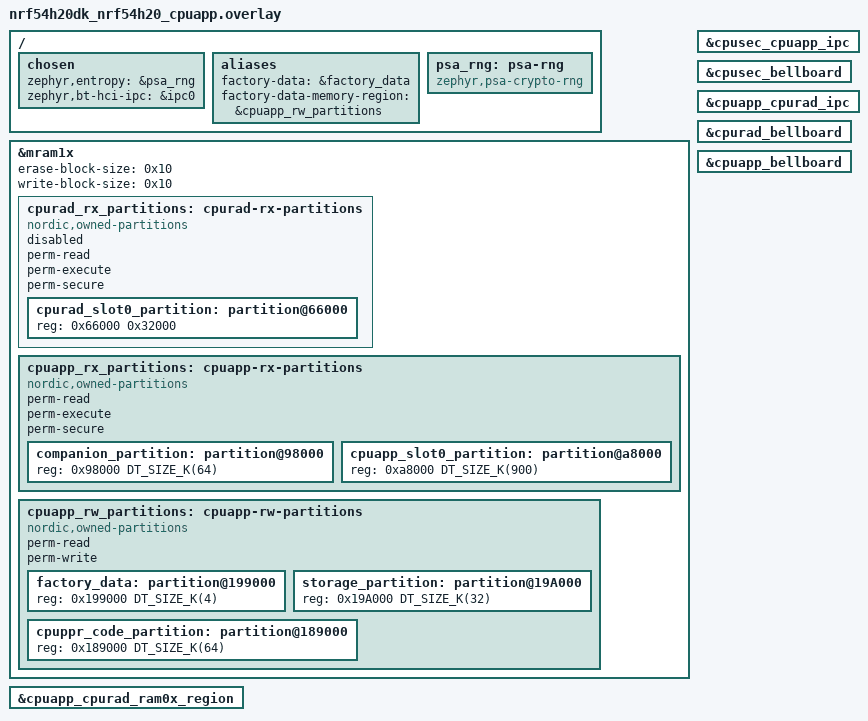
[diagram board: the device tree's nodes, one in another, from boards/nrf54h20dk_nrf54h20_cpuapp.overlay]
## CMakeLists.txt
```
#
# Copyright (c) 2021 Nordic Semiconductor ASA
#
# SPDX-License-Identifier: LicenseRef-Nordic-5-Clause
#

cmake_minimum_required(VERSION 3.20.0)

find_package(Zephyr REQUIRED HINTS $ENV{ZEPHYR_BASE})
project(matter-lock)

# Enable GNU STD support.
include(${ZEPHYR_CONNECTEDHOMEIP_MODULE_DIR}/config/nrfconnect/app/enable-gnu-std.cmake)

# NORDIC SDK APP START

# Include Data Model utils
include(${ZEPHYR_NRF_MODULE_DIR}/samples/matter/common/cmake/data_model.cmake)

target_include_directories(app PRIVATE
    src
    ${CONFIG_NCS_MATTER_ZAP_FILES_PATH}
)

SET(access_srcs src/access/access_data_types.cpp
              src/access/access_manager_credentials.cpp
              src/access/access_manager_users.cpp
              src/access/access_manager.cpp
              src/access/access_storage.cpp
              )

if(CONFIG_LOCK_SCHEDULES)
    LIST(APPEND access_srcs src/access/access_manager_schedules.cpp)
endif()

target_sources(app PRIVATE
    src/app_task.cpp
    src/bolt_lock_manager.cpp
    src/main.cpp
    src/zcl_callbacks.cpp
    ${access_srcs}
)

if(CONFIG_THREAD_WIFI_SWITCHING)
    target_sources(app PRIVATE
        src/thread_wifi_switch.cpp
    )
endif()

# Do not treat warnings as errors while the variable may be uninitialized for this sample data model.
# In the door-lock-server implementation, there is a warning that the C++ "optional"
# variable may be uninitialized, but actually, it is wrongly interpreted by the Zephyr toolchain.
target_compile_options(matter-data-model PRIVATE -Wno-error=maybe-uninitialized)

ncs_configure_data_model(
    ZAP_FILE ${CMAKE_CURRENT_SOURCE_DIR}/${CONFIG_NCS_MATTER_ZAP_FILES_PATH}/lock.zap
)

# NORDIC SDK APP END
```

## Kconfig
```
#
# Copyright (c) 2021 Nordic Semiconductor
#
# SPDX-License-Identifier: LicenseRef-Nordic-5-Clause
#

mainmenu "Matter Lock sample application"

config LOCK_MAX_NUM_USERS
	int "Maximum number of users supported by the lock"
	default 10

config LOCK_MAX_NUM_CREDENTIALS_PER_USER
	int "Maximum total number of credentials per one user supported by the lock"
	default 4

config LOCK_MAX_NUM_CREDENTIALS_PER_TYPE
	int "Maximum number of credentials of given type supported by the lock"
	default 15

config LOCK_MAX_CREDENTIAL_LENGTH
	int "Maximum length of the single credential supported by the lock"
	default 10

config LOCK_PASS_CREDENTIALS_TO_SET_LOCK_STATE
	bool "Pass used credentials when setting the lock state"
	help
	  This option should stay disabled until TC-DRLK-2.3 is fixed.
	  Related issue: https://github.com/project-chip/connectedhomeip/issues/38222

config LOCK_SCHEDULES
	bool "Support for WeekDay, YearDay and Holiday schedules in lock"
	help
	  This option adds support for an optional Timed Schedule Access Lock feature.
	  You can use Week Day, Year Day and Holiday schedules to restrict access for a
	  specific user for a defined time window. For example, use it to
	  give the user access only for three days in week.

if LOCK_SCHEDULES

config LOCK_MAX_WEEKDAY_SCHEDULES_PER_USER
	int "Maximum number of WeekDay schedules per one user supported by the lock"
	default 5

config LOCK_MAX_YEARDAY_SCHEDULES_PER_USER
	int "Maximum number of YearDay schedules per one user supported by the lock"
	default 5

config LOCK_MAX_HOLIDAY_SCHEDULES
	int "Maximum number of Holiday schedules supported by the lock"
	default 5

endif

config LOCK_ENABLE_DEBUG
	bool "Enable debug features to print users and credentials"
	depends on SHELL
	help
	  Debug features allows to checking and printing current users, their state, and
	  associated credentials. Use these with shell commands combinations to read saved credentials
	  or users, and manage them (add, clear, read).

if LOCK_ENABLE_DEBUG

config LOCK_PRINT_STORAGE_STATUS
	bool "Print storage status after each store call"
	help
	  Debug feature to print the debug-level log that contains information of the entry being stored
	  to persistent storage and how many bytes are left to store the new entry. It can be used to verify
	  whether credential, schedule or user entries are written properly to persistent storage.
	  This option should be disabled in production firmware
	  version.

# This should be deterined based on the maximum possible command length that depends on the LOCK_MAX_CREDENTIAL_LENGTH
config SHELL_CMD_BUFF_SIZE
	default 300

endif

config STATE_LEDS
	bool "Use LEDs to indicate the device state"
	default y
	help
	  Use LEDs to render the current state of the device such as the progress of commissioning of
	  the device into a network or the factory reset initiation. Note that setting this option to
	  'n' does not disable the LED indicating the state of the simulated bolt.

config THREAD_WIFI_SWITCHING
	bool "Switching between Thread and Wi-Fi"
	depends on SOC_SERIES_NRF53X
	depends on NET_L2_OPENTHREAD
	depends on CHIP_WIFI
	depends on !CHIP_FACTORY_RESET_ERASE_SETTINGS
	select EXPERIMENTAL
	help
	  Build the application with both Thread and Wi-Fi support and initialize
	  either transport based on the current configuration. A user can switch
	  between Thread and Wi-Fi by pressing and holding Button 3 for more than
	  10 seconds. During the switching, the device is automatically factory
	  reset and rebooted.

if THREAD_WIFI_SWITCHING

config THREAD_WIFI_SWITCHING_SHELL
	bool "Shell command for switching between Thread and Wi-Fi"
	default y if SHELL
	help
	  Add "switch_transport" shell command that initiates switching between
	  Thread and Wi-Fi transport for Matter protocol stack.

endif # THREAD_WIFI_SWITCHING

# Sample configuration used for Thread networking
if OPENTHREAD

choice OPENTHREAD_NORDIC_LIBRARY_CONFIGURATION
	default OPENTHREAD_NORDIC_LIBRARY_MTD
endchoice

choice OPENTHREAD_DEVICE_TYPE
	default OPENTHREAD_MTD
endchoice

config CHIP_ENABLE_ICD_SUPPORT
	default y

# Reduce Thread TX output power to 0 dBm for SED device
config OPENTHREAD_DEFAULT_TX_POWER
	int
	default 0

endif # OPENTHREAD

if CHIP_WIFI

config NRF_WIFI_LOW_POWER
	default y

endif # CHIP_WIFI

config NCS_MATTER_PERSISTENT_STORAGE
	default y

# PSA SSF Crypto Client is not ready for the secure storage backend
if !PSA_SSF_CRYPTO_CLIENT

config NCS_MATTER_SECURE_STORAGE_BACKEND
	default y if !CHIP_WIFI

config NCS_MATTER_SETTINGS_STORAGE_BACKEND
	default n if !CHIP_WIFI

endif

# Increase the storage capacity if the schedules are enabled with secure storage
# This also implies increasing of the OT and Matter stacks because some operations
# performed during commissioning seem to allocate stack buffers based on the
# maximum possible secure asset size.
if LOCK_SCHEDULES && NCS_MATTER_SECURE_STORAGE_BACKEND

config NCS_MATTER_SECURE_STORAGE_MAX_ENTRY_NUMBER
	default 128

config TRUSTED_STORAGE_BACKEND_AEAD_MAX_DATA_SIZE
	default 3072

config OPENTHREAD_THREAD_STACK_SIZE
	default 7168

config CHIP_TASK_STACK_SIZE
	default 10240

config MAIN_STACK_SIZE
	default 7168

endif

source "${ZEPHYR_CONNECTEDHOMEIP_MODULE_DIR}/config/nrfconnect/chip-module/Kconfig.features"
source "${ZEPHYR_CONNECTEDHOMEIP_MODULE_DIR}/config/nrfconnect/chip-module/Kconfig.defaults"
source "${ZEPHYR_NRF_MODULE_DIR}/samples/matter/common/src/Kconfig"
source "Kconfig.zephyr"
```

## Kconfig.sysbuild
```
#
# Copyright (c) 2023 Nordic Semiconductor ASA
#
# SPDX-License-Identifier: LicenseRef-Nordic-5-Clause
#

config PARTITION_MANAGER
	default n if (SOC_SERIES_NRF52X || SOC_NRF54L15 || SOC_NRF54LM20A) && \
		!TRUSTED_EXECUTION_NONSECURE

# This config has to be enabled manually for variants with shields, because sysbuild does not support it.
config WIFI_NRF70
	default y if BOARD_NRF7002DK

#### Radio core selection
config NRF_DEFAULT_IPC_RADIO
	default y

# Enable IEEE802.15.4 serialization to network core
# This config automatically pulls in the `overlay-802154.conf` in the ipc_radio image
config NETCORE_IPC_RADIO_IEEE802154
	default y if SOC_SERIES_NRF53X && !WIFI_NRF70

# Enable Bluetooth serialization to network core
# This config automatically pulls in the `overlay-bt_hci_ipc.conf` in the ipc_radio image
config NETCORE_IPC_RADIO_BT_HCI_IPC
	default y if SOC_SERIES_NRF53X

#### Bootloader
choice BOOTLOADER
	default BOOTLOADER_MCUBOOT if !BOARD_NRF21540DK
endchoice

if BOOTLOADER_MCUBOOT

#### DFU multi-image support
config DFU_MULTI_IMAGE_PACKAGE_BUILD
	default y

config DFU_MULTI_IMAGE_PACKAGE_APP
	default y

config PM_EXTERNAL_FLASH_MCUBOOT_SECONDARY
	default y

#### DFU network core configuration
if SOC_SERIES_NRF53X

choice MCUBOOT_MODE
	default MCUBOOT_MODE_OVERWRITE_ONLY
endchoice

choice BOOT_SIGNATURE_TYPE
	default BOOT_SIGNATURE_TYPE_RSA
endchoice

config SECURE_BOOT_NETCORE
	default y

config NETCORE_APP_UPDATE
	default y

config DFU_MULTI_IMAGE_PACKAGE_NET
	default y

endif # SOC_SERIES_NRF53X

if BOARD_NRF54L15DK || BOARD_NRF54LM20DK

# Disable checking the external drivers for nRF54L15 and nRF54LM20 DKs.
config PM_OVERRIDE_EXTERNAL_DRIVER_CHECK
	default y

endif # BOARD_NRF54L15DK || BOARD_NRF54LM20DK

endif # BOOTLOADER_MCUBOOT

# Store the Wi-Fi firmware patch on external flash by default for nRF5340 with nRF7002
if WIFI_NRF70 && SOC_NRF5340_CPUAPP

choice WIFI_PATCHES_EXT_FLASH_SUPPORT
	default WIFI_PATCHES_EXT_FLASH_STORE

endchoice

config DFU_MULTI_IMAGE_PACKAGE_WIFI_FW_PATCH
	default y

endif # WIFI_NRF70

#### Enable generating factory data
config MATTER_FACTORY_DATA_GENERATE
	default y if !BOARD_NRF21540DK

source "share/sysbuild/Kconfig"
```

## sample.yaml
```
sample:
  description: Matter Lock example
  name: Matter Lock
tests:
  sample.matter.lock.debug:
    sysbuild: true
    build_only: true
    integration_platforms:
      - nrf52840dk/nrf52840
      - nrf5340dk/nrf5340/cpuapp
      - nrf7002dk/nrf5340/cpuapp
      - nrf7002dk/nrf5340/cpuapp/nrf7001
      - nrf54l15pdk/nrf54l15/cpuapp
      - nrf54h20dk/nrf54h20/cpuapp
    platform_allow: nrf52840dk/nrf52840 nrf5340dk/nrf5340/cpuapp nrf7002dk/nrf5340/cpuapp
      nrf7002dk/nrf5340/cpuapp/nrf7001 nrf54l15pdk/nrf54l15/cpuapp
      nrf54h20dk/nrf54h20/cpuapp
    tags: sysbuild
  sample.matter.lock.release:
    sysbuild: true
    build_only: true
    extra_args: FILE_SUFFIX=release
    integration_platforms:
      - nrf52840dk/nrf52840
      - nrf5340dk/nrf5340/cpuapp
      - nrf7002dk/nrf5340/cpuapp
      - nrf7002dk/nrf5340/cpuapp/nrf7001
      - nrf54l15pdk/nrf54l15/cpuapp
    platform_allow: nrf52840dk/nrf52840 nrf5340dk/nrf5340/cpuapp nrf7002dk/nrf5340/cpuapp
      nrf7002dk/nrf5340/cpuapp/nrf7001 nrf54l15pdk/nrf54l15/cpuapp
    tags: sysbuild
  sample.matter.lock.lto:
    sysbuild: true
    build_only: true
    extra_args: CONFIG_LTO=y CONFIG_ISR_TABLES_LOCAL_DECLARATION=y
    integration_platforms:
      - nrf52840dk/nrf52840
      - nrf5340dk/nrf5340/cpuapp
      - nrf7002dk/nrf5340/cpuapp
      - nrf7002dk/nrf5340/cpuapp/nrf7001
      - nrf54l15pdk/nrf54l15/cpuapp
    platform_allow: nrf52840dk/nrf52840 nrf5340dk/nrf5340/cpuapp nrf7002dk/nrf5340/cpuapp
      nrf7002dk/nrf5340/cpuapp/nrf7001 nrf54l15pdk/nrf54l15/cpuapp
    tags: sysbuild
  sample.matter.lock.smp_dfu:
    sysbuild: true
    build_only: true
    extra_args: CONFIG_CHIP_DFU_OVER_BT_SMP=y
    integration_platforms:
      - nrf52840dk/nrf52840
      - nrf5340dk/nrf5340/cpuapp
      - nrf7002dk/nrf5340/cpuapp
      - nrf7002dk/nrf5340/cpuapp/nrf7001
      - nrf54l15pdk/nrf54l15/cpuapp
    platform_allow: nrf52840dk/nrf52840 nrf5340dk/nrf5340/cpuapp nrf7002dk/nrf5340/cpuapp
      nrf7002dk/nrf5340/cpuapp/nrf7001 nrf54l15pdk/nrf54l15/cpuapp
    tags: sysbuild
  sample.matter.lock.no_dfu.no_fd:
    sysbuild: true
    build_only: true
    integration_platforms:
      - nrf21540dk/nrf52840
    platform_allow: >
      nrf21540dk/nrf52840
    tags: sysbuild
  sample.matter.lock.thread_wifi_switched.lto.smp_dfu:
    sysbuild: true
    build_only: true
    extra_args: lock_SHIELD=nrf7002ek multiprotocol_rpmsg_SHIELD=nrf7002ek_coex
      FILE_SUFFIX=thread_wifi_switched SB_CONFIG_WIFI_PATCHES_EXT_FLASH_STORE=y
      SB_CONFIG_MCUBOOT_UPDATEABLE_IMAGES=3 CONFIG_CHIP_DFU_OVER_BT_SMP=y
      SB_CONFIG_WIFI_NRF700X=y SB_CONFIG_DFU_MULTI_IMAGE_PACKAGE_WIFI_FW_PATCH=y
    integration_platforms:
      - nrf5340dk/nrf5340/cpuapp
    platform_allow: nrf5340dk/nrf5340/cpuapp
    tags: sysbuild
  sample.matter.lock.nus:
    sysbuild: true
    build_only: true
    extra_args: CONFIG_CHIP_NUS=y CONFIG_BT_FIXED_PASSKEY=y CONFIG_CHIP_NUS_FIXED_PASSKEY=112233
    integration_platforms:
      - nrf52840dk/nrf52840
      - nrf5340dk/nrf5340/cpuapp
    platform_allow: nrf52840dk/nrf52840 nrf5340dk/nrf5340/cpuapp
    tags: sysbuild
  samples.matter.lock.certification:
    sysbuild: true
    build_only: true
    extra_args: lock_SNIPPET=diagnostic-logs
    integration_platforms:
      - nrf52840dk/nrf52840
      - nrf5340dk/nrf5340/cpuapp
      - nrf54l15pdk/nrf54l15/cpuapp
    platform_allow: nrf52840dk/nrf52840 nrf5340dk/nrf5340/cpuapp nrf54l15pdk/nrf54l15/cpuapp
    tags: sysbuild
```

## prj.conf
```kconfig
#
# Copyright (c) 2022 Nordic Semiconductor ASA
#
# SPDX-License-Identifier: LicenseRef-Nordic-5-Clause
#

# This sample uses Kconfig.defaults to set options common for all
# samples. This file should contain only options specific for this sample
# or overrides of default values.

# Enable CHIP
CONFIG_CHIP=y
CONFIG_CHIP_PROJECT_CONFIG="src/chip_project_config.h"
# 32774 == 0x8006 (example lock-app)
CONFIG_CHIP_DEVICE_PRODUCT_ID=32774
CONFIG_STD_CPP17=y

# Enable Matter extended announcement and increase duration to 1 hour.
CONFIG_CHIP_BLE_EXT_ADVERTISING=y
CONFIG_CHIP_BLE_ADVERTISING_DURATION=60

# Add support for LEDs and buttons on Nordic development kits
CONFIG_DK_LIBRARY=y

# Bluetooth Low Energy configuration
CONFIG_BT_DEVICE_NAME="MatterLock"

# Suspend devices when the CPU goes into sleep
CONFIG_PM_DEVICE=y

# Other settings
CONFIG_THREAD_NAME=y
CONFIG_MPU_STACK_GUARD=y
CONFIG_RESET_ON_FATAL_ERROR=n
CONFIG_CHIP_LIB_SHELL=y
CONFIG_NCS_MATTER_TEST_SHELL=y

# Reduce application size
CONFIG_USE_SEGGER_RTT=n
CONFIG_MATTER_LOG_LEVEL_INF=y
CONFIG_CHIP_APP_LOG_LEVEL=3

# Enable Factory Data feature
CONFIG_CHIP_FACTORY_DATA=y
CONFIG_CHIP_FACTORY_DATA_BUILD=y
```

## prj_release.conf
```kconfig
#
# Copyright (c) 2022 Nordic Semiconductor ASA
#
# SPDX-License-Identifier: LicenseRef-Nordic-5-Clause
#

# This sample uses Kconfig.defaults to set options common for all
# samples. This file should contain only options specific for this sample
# or overrides of default values.

# Enable CHIP
CONFIG_CHIP=y
CONFIG_CHIP_PROJECT_CONFIG="src/chip_project_config.h"
# 32774 == 0x8006 (example lock-app)
CONFIG_CHIP_DEVICE_PRODUCT_ID=32774
CONFIG_STD_CPP17=y

# Enable Matter extended announcement and increase duration to 1 hour.
CONFIG_CHIP_BLE_EXT_ADVERTISING=y
CONFIG_CHIP_BLE_ADVERTISING_DURATION=60

# Add support for LEDs and buttons on Nordic development kits
CONFIG_DK_LIBRARY=y

# Bluetooth Low Energy configuration
CONFIG_BT_DEVICE_NAME="MatterLock"

# Suspend devices when the CPU goes into sleep
CONFIG_PM_DEVICE=y

# Enable system reset on fatal error
CONFIG_RESET_ON_FATAL_ERROR=y

# Try to disable unused RAM blocks to reduce power consumption
CONFIG_RAM_POWER_DOWN_LIBRARY=y

# Disable all debug features
CONFIG_USE_SEGGER_RTT=n
CONFIG_SHELL=n
CONFIG_OPENTHREAD_SHELL=n
CONFIG_CONSOLE=n
CONFIG_UART_CONSOLE=n
CONFIG_SERIAL=n
CONFIG_LOG=n
CONFIG_LOG_MODE_MINIMAL=n
CONFIG_ASSERT_VERBOSE=n
CONFIG_ASSERT_NO_FILE_INFO=y
CONFIG_PRINTK=n
CONFIG_PRINTK_SYNC=n
CONFIG_THREAD_NAME=n
CONFIG_BOOT_BANNER=n

# Enable Factory Data feature
CONFIG_CHIP_FACTORY_DATA=y
CONFIG_CHIP_FACTORY_DATA_BUILD=y

# Enable Watchdog
CONFIG_NCS_MATTER_WATCHDOG=y

# Enable LTO to decrease the flash usage.
CONFIG_LTO=y
CONFIG_ISR_TABLES_LOCAL_DECLARATION=y
```

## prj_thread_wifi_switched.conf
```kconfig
#
# Copyright (c) 2022 Nordic Semiconductor ASA
#
# SPDX-License-Identifier: LicenseRef-Nordic-5-Clause
#

# This sample uses Kconfig.defaults to set options common for all
# samples. This file should contain only options specific for this sample
# or overrides of default values.

# Enable CHIP
CONFIG_CHIP=y
CONFIG_CHIP_PROJECT_CONFIG="src/chip_project_config.h"
# 32774 == 0x8006 (example lock-app)
CONFIG_CHIP_DEVICE_PRODUCT_ID=32774
CONFIG_STD_CPP17=y

# Enable Matter extended announcement and increase duration to 1 hour.
CONFIG_CHIP_BLE_EXT_ADVERTISING=y
CONFIG_CHIP_BLE_ADVERTISING_DURATION=60

# Add support for LEDs and buttons on Nordic development kits
CONFIG_DK_LIBRARY=y

# Bluetooth Low Energy configuration
CONFIG_BT_DEVICE_NAME="MatterLock"

# Other settings
CONFIG_MPU_STACK_GUARD=y
CONFIG_RESET_ON_FATAL_ERROR=n

# Enable switching between Thread and Wi-Fi variants
CONFIG_THREAD_WIFI_SWITCHING=y
CONFIG_THREAD_WIFI_SWITCHING_SHELL=y
CONFIG_CHIP_WIFI=y
CONFIG_NET_L2_OPENTHREAD=y
CONFIG_CHIP_FACTORY_RESET_ERASE_NVS=n # Do not restore initial transport on factory reset

# Reduce application size
CONFIG_USE_SEGGER_RTT=n
CONFIG_WPA_SUPP_ADVANCED_FEATURES=n
CONFIG_CHIP_NFC_COMMISSIONING=n
CONFIG_MATTER_LOG_LEVEL_INF=y
CONFIG_CHIP_APP_LOG_LEVEL=3
CONFIG_THREAD_NAME=n
CONFIG_BOOT_BANNER=n

# Enable Factory Data feature
CONFIG_CHIP_FACTORY_DATA=y
CONFIG_CHIP_FACTORY_DATA_BUILD=y

# Enable LTO
# CONFIG_LTO=y
# CONFIG_ISR_TABLES_LOCAL_DECLARATION=y

# Enforce the use of mbedTLS crypto backend instead of PSA Crypto by
# building OpenThread from sources. Wi-Fi stack does not support PSA Crypto yet.
CONFIG_OPENTHREAD_SOURCES=y
```

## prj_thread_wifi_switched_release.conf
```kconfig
#
# Copyright (c) 2022 Nordic Semiconductor ASA
#
# SPDX-License-Identifier: LicenseRef-Nordic-5-Clause
#

# This sample uses Kconfig.defaults to set options common for all
# samples. This file should contain only options specific for this sample
# or overrides of default values.

# Enable CHIP
CONFIG_CHIP=y
CONFIG_CHIP_PROJECT_CONFIG="src/chip_project_config.h"
# 32774 == 0x8006 (example lock-app)
CONFIG_CHIP_DEVICE_PRODUCT_ID=32774
CONFIG_STD_CPP17=y

# Enable Matter extended announcement and increase duration to 1 hour.
CONFIG_CHIP_BLE_EXT_ADVERTISING=y
CONFIG_CHIP_BLE_ADVERTISING_DURATION=60

# Add support for LEDs and buttons on Nordic development kits
CONFIG_DK_LIBRARY=y

# Bluetooth Low Energy configuration
CONFIG_BT_DEVICE_NAME="MatterLock"

# Other settings
CONFIG_RESET_ON_FATAL_ERROR=y

# Enable switching between Thread and Wi-Fi variants
CONFIG_THREAD_WIFI_SWITCHING=y
CONFIG_CHIP_WIFI=y
CONFIG_NET_L2_OPENTHREAD=y
CONFIG_CHIP_FACTORY_RESET_ERASE_NVS=n # Do not restore initial transport on factory reset

# Disable all debug features
CONFIG_USE_SEGGER_RTT=n
CONFIG_SHELL=n
CONFIG_OPENTHREAD_SHELL=n
CONFIG_CONSOLE=n
CONFIG_UART_CONSOLE=n
CONFIG_SERIAL=n
CONFIG_LOG=n
CONFIG_LOG_MODE_MINIMAL=n
CONFIG_ASSERT_VERBOSE=n
CONFIG_ASSERT_NO_FILE_INFO=y
CONFIG_PRINTK=n
CONFIG_PRINTK_SYNC=n
CONFIG_THREAD_NAME=n
CONFIG_BOOT_BANNER=n

# Enable Factory Data feature
CONFIG_CHIP_FACTORY_DATA=y
CONFIG_CHIP_FACTORY_DATA_BUILD=y

# Enable LTO
# CONFIG_LTO=y
# CONFIG_ISR_TABLES_LOCAL_DECLARATION=y

# Enforce the use of mbedTLS crypto backend instead of PSA Crypto by
# building OpenThread from sources. Wi-Fi stack does not support PSA Crypto yet.
CONFIG_OPENTHREAD_SOURCES=y

# Enable Time Sync Schedules clusters
CONFIG_LOCK_SCHEDULES=y
CONFIG_LOCK_ENABLE_DEBUG=y
CONFIG_CHIP_ENABLE_READ_CLIENT=y
```

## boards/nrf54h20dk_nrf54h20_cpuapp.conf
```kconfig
#
# Copyright (c) 2024 Nordic Semiconductor ASA
#
# SPDX-License-Identifier: LicenseRef-Nordic-5-Clause
#

# TODO: Workaround to be removed once DFU and external flash will be supported on nRF54H20.
CONFIG_CHIP_OTA_REQUESTOR=n
CONFIG_CHIP_QSPI_NOR=n

CONFIG_MPU_STACK_GUARD=n

# TODO: Enable PSA crypto once it is available
CONFIG_CHIP_CRYPTO_PSA=n
CONFIG_MBEDTLS_CIPHER_PADDING_PKCS7=y
CONFIG_MBEDTLS_CIPHER_MODE_CBC=y

# TODO: Enable factory data once it is available
CONFIG_CHIP_FACTORY_DATA=n

# TODO: Workaround to be removed once Zephyr's CONFIG_FPROTECT is supported on nRF54H20.
CONFIG_CHIP_FACTORY_DATA_WRITE_PROTECT=n

# Use common SUIT envelope templates prepared for Matter purpose
CONFIG_SUIT_ENVELOPE_TEMPLATE="${ZEPHYR_NRF_MODULE_DIR}/samples/matter/common/suit_templates/app_envelope.yaml.jinja2"

# Prepare SUIT to work with the external flash
CONFIG_SUIT_DFU_CANDIDATE_PROCESSING_FULL=y
CONFIG_SUIT_STREAM_SOURCE_FLASH=y
CONFIG_SUIT_CACHEX_ERASE_ON_INIT=y
```

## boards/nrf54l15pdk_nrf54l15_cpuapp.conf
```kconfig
#
# Copyright (c) 2024 Nordic Semiconductor ASA
#
# SPDX-License-Identifier: LicenseRef-Nordic-5-Clause
#

# Multirole is the only currently supported role by SoftDevice.
CONFIG_BT_LL_SOFTDEVICE_MULTIROLE=y

CONFIG_FPU=n

# nRF54L15 requires bigger stack sizes than nRF52/nRF53 families
CONFIG_CHIP_MALLOC_SYS_HEAP_SIZE=10240
CONFIG_MPSL_WORK_STACK_SIZE=2048
CONFIG_CHIP_TASK_STACK_SIZE=7168

# Set the NVS sector count to match the settings partition size that is 40 kB for this application.
CONFIG_SETTINGS_NVS_SECTOR_COUNT=10

# Enable Low power
CONFIG_POWEROFF=y
CONFIG_SOC_NRF_FORCE_CONSTLAT=n
CONFIG_POWER_DOMAIN=y
```

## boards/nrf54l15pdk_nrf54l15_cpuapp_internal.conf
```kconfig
#
# Copyright (c) 2024 Nordic Semiconductor ASA
#
# SPDX-License-Identifier: LicenseRef-Nordic-5-Clause
#

# Multirole is the only currently supported role by SoftDevice.
CONFIG_BT_LL_SOFTDEVICE_MULTIROLE=y

# TODO: Workaround to be removed once Zephyr's CONFIG_FPROTECT is supported on nRF54L
CONFIG_CHIP_FACTORY_DATA_WRITE_PROTECT=n

# nRF54L15 requires bigger stack sizes than nRF52/nRF53 families
CONFIG_CHIP_MALLOC_SYS_HEAP_SIZE=10240
CONFIG_MPSL_WORK_STACK_SIZE=2048
CONFIG_CHIP_TASK_STACK_SIZE=7168

# Set the NVS sector count to match the settings partition size that is 40 kB for this application.
CONFIG_SETTINGS_NVS_SECTOR_COUNT=10

# Low power mode
CONFIG_POWEROFF=y
CONFIG_SOC_NRF_FORCE_CONSTLAT=n

# Disable redundant SPI
CONFIG_CHIP_SPI_NOR=n

# Release Configuration

# Enable system reset on fatal error
CONFIG_RESET_ON_FATAL_ERROR=y

# Disable all debug features
CONFIG_THREAD_NAME=n
CONFIG_MPU_STACK_GUARD=n
CONFIG_CHIP_LIB_SHELL=n
CONFIG_USE_SEGGER_RTT=n
CONFIG_SHELL=n
CONFIG_OPENTHREAD_SHELL=n
CONFIG_CONSOLE=n
CONFIG_UART_CONSOLE=n
CONFIG_SERIAL=n
CONFIG_LOG=n
CONFIG_LOG_MODE_MINIMAL=n
CONFIG_ASSERT_VERBOSE=n
CONFIG_ASSERT_NO_FILE_INFO=y
CONFIG_PRINTK=n
CONFIG_PRINTK_SYNC=n
CONFIG_THREAD_NAME=n
CONFIG_BOOT_BANNER=n

# Enable Watchdog
# CONFIG_NCS_SAMPLE_MATTER_WATCHDOG=y

CONFIG_CHIP_ENABLE_PAIRING_AUTOSTART=y
CONFIG_DK_LIBRARY=n

# Enable LTO
# CONFIG_LTO=y
# CONFIG_ISR_TABLES_LOCAL_DECLARATION=y
```

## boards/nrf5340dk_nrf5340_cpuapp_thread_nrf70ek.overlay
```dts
/*
 * Copyright (c) 2021 Nordic Semiconductor ASA
 *
 * SPDX-License-Identifier: LicenseRef-Nordic-5-Clause
 */

#include <samples/matter/nrf7002_partitions.dtsi>
#include <zephyr/dt-bindings/ipc_service/static_vrings.h>

/* Set IPC thread priority to the highest value to not collide with other threads. */
&ipc0 {
	zephyr,priority = <0 PRIO_COOP>;
};

/* Disable unused peripherals to reduce power consumption */
&adc {
	status = "disabled";
};

&i2c1 {
	status = "disabled";
};

&pwm0 {
	status = "disabled";
};

&spi2 {
	status = "disabled";
};

&usbd {
	status = "disabled";
};
```

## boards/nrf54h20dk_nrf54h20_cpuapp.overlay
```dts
/*
* Copyright (c) 2023 Nordic Semiconductor ASA
*
* SPDX-License-Identifier: LicenseRef-Nordic-5-Clause
*/

/**************************************************************
Chosen assignment and aliases
**************************************************************/
/ {
	chosen {
		zephyr,entropy = &psa_rng;
		/* prepare IPC to HCI Radio core */
		zephyr,bt-hci-ipc = &ipc0;
	};
	
	aliases {
		factory-data = &factory_data;
		factory-data-memory-region = &cpuapp_rw_partitions;
	};
};

/**************************************************************
Delete unused nRF54L15 peripherals and nodes
**************************************************************/
/* Matter sample does not use viper core */
// /delete-node/ &cpuppr_vpr;

/* We need to redefine partitions to meet Matter requirements */
/delete-node/ &cpuapp_rx_partitions;
/delete-node/ &cpuapp_rw_partitions;
/delete-node/ &cpurad_rx_partitions;

/**************************************************************
Random number generator
**************************************************************/
/ {
	psa_rng: psa-rng {
		compatible = "zephyr,psa-crypto-rng";
		status = "okay";
	};
};

/**************************************************************
Redefine MRAM memory (Partitions)
**************************************************************/
&mram1x {
	erase-block-size = < 0x10 >;
	/* Hardcoded inside the soc_flash_nrf_mram.c (MRAM_WORD_SIZE) */
	write-block-size = < 0x10 >;
	
	cpurad_rx_partitions: cpurad-rx-partitions {
		compatible = "nordic,owned-partitions", "fixed-partitions";
		status = "disabled";
		perm-read;
		perm-execute;
		perm-secure;
		#address-cells = < 0x1 >;
		#size-cells = < 0x1 >;
		cpurad_slot0_partition: partition@66000 {
			reg = < 0x66000 0x32000 >;
		};
	};
	
	cpuapp_rx_partitions: cpuapp-rx-partitions {
		compatible = "nordic,owned-partitions", "fixed-partitions";
		status = "okay";
		perm-read;
		perm-execute;
		perm-secure;
		#address-cells = <1>;
		#size-cells = <1>;
		
		companion_partition: partition@98000 {
			reg = <0x98000 DT_SIZE_K(64)>;
		};
		
		cpuapp_slot0_partition: partition@a8000 {
			reg = <0xa8000 DT_SIZE_K(900)>;
		};
	};
	
	cpuapp_rw_partitions: cpuapp-rw-partitions {
		compatible = "nordic,owned-partitions", "fixed-partitions";
		status = "okay";
		perm-read;
		perm-write;
		#address-cells = < 0x1 >;
		#size-cells = < 0x1 >;
		
		factory_data: partition@199000 {
			reg = < 0x199000 DT_SIZE_K(4) >;
		};
		storage_partition: partition@19A000 {
			reg = < 0x19A000 DT_SIZE_K(32) >;
		};
		cpuppr_code_partition: partition@189000 {
			reg = <0x189000 DT_SIZE_K(64)>;
		};
	};
};

/**************************************************************
Enable IPC to other domains
**************************************************************/


/**************************************************************
Enable required peripherals
**************************************************************/
/* Communication between Application Core and Secure Domain*/
&cpusec_cpuapp_ipc {
	status = "okay";
};

/* Communication between Application and Radio Cores in WiFi build */
&cpusec_bellboard {
	status = "okay";
};
ipc0: &cpuapp_cpurad_ipc {
	status = "okay";
};
&cpuapp_cpurad_ram0x_region {
	status = "okay";
};
&cpurad_bellboard {
	status = "okay";
};
&cpuapp_bellboard {
	status = "okay";
};
```

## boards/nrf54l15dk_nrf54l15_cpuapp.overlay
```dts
/*
 * Copyright (c) 2024 Nordic Semiconductor ASA
 *
 * SPDX-License-Identifier: LicenseRef-Nordic-5-Clause
 */

#include "../../common/boards/nrf54l15dk_nrf54l15_cpuapp_partitions.dtsi"

/ {
	aliases {
		/* Use watchdog wdt31 as the application watchdog */
		watchdog0 = &wdt31;
	};

	chosen {
		nordic,pm-ext-flash = &mx25r64;
	};
};

/* TODO: re-enable HWFC once it's fixed */
&uart20 {
	/delete-property/ hw-flow-control;
};

&wdt31 {
	status = "okay";
};
```

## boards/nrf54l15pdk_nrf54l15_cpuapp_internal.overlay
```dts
/*
 * Copyright (c) 2024 Nordic Semiconductor ASA
 *
 * SPDX-License-Identifier: LicenseRef-Nordic-5-Clause
 */

/ {
	aliases {
		// Use watchdog wdt31 as the application watchdog
		watchdog0 = &wdt31;
	};
};

// restore full RRAM and SRAM space - by default some parts are dedicated to FLRP
&cpuapp_rram {
	reg = <0x0 DT_SIZE_K(1524)>;
};

&cpuapp_sram {
	reg = <0x20000000 DT_SIZE_K(256)>;
	ranges = <0x0 0x20000000  0x40000>;
};

// TODO: re-enable HWFC once it's fixed
&uart20 {
	/delete-property/ hw-flow-control;
	status = "disabled";
};

&mx25r64 {
	status = "disabled";
};

&spi00 {
	status = "disabled";
};

&wdt31 {
	status = "disabled";
};

&pwm20 {
	status = "disabled";
};

&adc {
	status = "disabled";
};
```

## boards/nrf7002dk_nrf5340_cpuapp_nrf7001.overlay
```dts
/*
 * Copyright (c) 2021 Nordic Semiconductor ASA
 *
 * SPDX-License-Identifier: LicenseRef-Nordic-5-Clause
 */

#include <samples/matter/nrf7002_partitions.dtsi>
#include <zephyr/dt-bindings/ipc_service/static_vrings.h>

/ {
	chosen {
		nordic,pm-ext-flash = &mx25r64;
	};

	aliases {
		watchdog0 = &wdt0;
	};
};

/* Set IPC thread priority to the highest value to not collide with other threads. */
&ipc0 {
	zephyr,priority = <0 PRIO_COOP>;
};
```

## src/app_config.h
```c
/*
 * Copyright (c) 2022 Nordic Semiconductor ASA
 *
 * SPDX-License-Identifier: LicenseRef-Nordic-5-Clause
 */

#pragma once

/* ---- Lock Example App Config ---- */
```

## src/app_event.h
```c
/*
 * Copyright (c) 2021 Nordic Semiconductor ASA
 *
 * SPDX-License-Identifier: LicenseRef-Nordic-5-Clause
 */

#pragma once

enum class AppEventType : uint8_t { None = 0, NUSCommand, LockEvent, ThreadWiFiSwitch };

struct AppEvent {
	AppEvent(AppEventType type) { mType = type; }
	AppEvent() = default;

	union {
		struct {
			void *Context;
		} LockEvent;
		struct {
			uint8_t ButtonAction;
		} ThreadWiFiSwitchEvent;
	};

	AppEventType mType;
};
```

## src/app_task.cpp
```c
/*
 * Copyright (c) 2021 Nordic Semiconductor ASA
 *
 * SPDX-License-Identifier: LicenseRef-Nordic-5-Clause
 */

#include "app_task.h"

#include "bolt_lock_manager.h"

#ifdef CONFIG_THREAD_WIFI_SWITCHING
#include "thread_wifi_switch.h"
#endif

#include "app/matter_init.h"
#include "app/task_executor.h"

#ifdef CONFIG_CHIP_NUS
#include "bt_nus/bt_nus_service.h"
#endif

#include <app-common/zap-generated/attributes/Accessors.h>
#include <app/clusters/door-lock-server/door-lock-server.h>
#include <app/clusters/identify-server/identify-server.h>
#include <platform/CHIPDeviceLayer.h>
#include <setup_payload/OnboardingCodesUtil.h>

#include <zephyr/logging/log.h>

LOG_MODULE_DECLARE(app, CONFIG_CHIP_APP_LOG_LEVEL);

using namespace ::chip;
using namespace ::chip::app;
using namespace ::chip::DeviceLayer;

namespace
{
constexpr EndpointId kLockEndpointId = 1;

#ifdef CONFIG_CHIP_NUS
constexpr uint16_t kAdvertisingIntervalMin = 400;
constexpr uint16_t kAdvertisingIntervalMax = 500;
constexpr uint8_t kLockNUSPriority = 2;
#endif

#ifdef CONFIG_THREAD_WIFI_SWITCHING
k_timer sSwitchTransportTimer;
constexpr uint32_t kSwitchTransportTimeout = 10000;
#endif

#define APPLICATION_BUTTON_MASK DK_BTN2_MSK
#define SWITCHING_BUTTON_MASK DK_BTN3_MSK

#ifndef CONFIG_CHIP_FACTORY_RESET_ERASE_SETTINGS
void AppFactoryResetHandler(const ChipDeviceEvent *event, intptr_t /* unused */)
{
	switch (event->Type) {
	case DeviceEventType::kFactoryReset:
		BoltLockMgr().FactoryReset();
		break;
	default:
		break;
	}
}
#endif

} /* namespace */

Identify sIdentify = { kLockEndpointId, AppTask::IdentifyStartHandler, AppTask::IdentifyStopHandler,
		       Clusters::Identify::IdentifyTypeEnum::kVisibleIndicator };

void AppTask::IdentifyStartHandler(Identify *)
{
	Nrf::PostTask(
		[] { Nrf::GetBoard().GetLED(Nrf::DeviceLeds::LED2).Blink(Nrf::LedConsts::kIdentifyBlinkRate_ms); });
}

void AppTask::IdentifyStopHandler(Identify *)
{
	Nrf::PostTask([] { Nrf::GetBoard().GetLED(Nrf::DeviceLeds::LED2).Set(BoltLockMgr().IsLocked()); });
}

void AppTask::ButtonEventHandler(Nrf::ButtonState state, Nrf::ButtonMask hasChanged)
{
	if ((APPLICATION_BUTTON_MASK & hasChanged) & state) {
		Nrf::PostTask([] { LockActionEventHandler(); });
	}

#ifdef CONFIG_THREAD_WIFI_SWITCHING
	if (SWITCHING_BUTTON_MASK & hasChanged) {
		SwitchButtonAction action =
			(SWITCHING_BUTTON_MASK & state) ? SwitchButtonAction::Pressed : SwitchButtonAction::Released;
		Nrf::PostTask([action] { SwitchTransportTriggerHandler(action); });
	}
#endif
}

void AppTask::LockActionEventHandler()
{
	if (BoltLockMgr().IsLocked()) {
		BoltLockMgr().Unlock(BoltLockManager::OperationSource::kButton);
	} else {
		BoltLockMgr().Lock(BoltLockManager::OperationSource::kButton);
	}
}

#ifdef CONFIG_THREAD_WIFI_SWITCHING
void AppTask::SwitchTransportEventHandler()
{
	LOG_INF("Switching to %s", ThreadWifiSwitch::IsThreadActive() ? "Wi-Fi" : "Thread");

	ThreadWifiSwitch::SwitchTransport();
}

void AppTask::SwitchTransportTimerTimeoutCallback(k_timer *timer)
{
	Nrf::PostTask([] { SwitchTransportEventHandler(); });
}

void AppTask::SwitchTransportTriggerHandler(const SwitchButtonAction &action)
{
	if (action == SwitchButtonAction::Pressed) {
		LOG_INF("Keep button pressed for %u ms to switch to %s", kSwitchTransportTimeout,
			ThreadWifiSwitch::IsThreadActive() ? "Wi-Fi" : "Thread");
		k_timer_start(&sSwitchTransportTimer, K_MSEC(kSwitchTransportTimeout), K_NO_WAIT);
	} else {
		LOG_INF("Switching to %s cancelled", ThreadWifiSwitch::IsThreadActive() ? "Wi-Fi" : "Thread");
		k_timer_stop(&sSwitchTransportTimer);
	}
}
#endif

void AppTask::LockStateChanged(const BoltLockManager::StateData &stateData)
{
	switch (stateData.mState) {
	case BoltLockManager::State::kLockingInitiated:
		LOG_INF("Lock action initiated");
		Nrf::GetBoard().GetLED(Nrf::DeviceLeds::LED2).Blink(50, 50);
#ifdef CONFIG_CHIP_NUS
		Nrf::GetNUSService().SendData("locking", sizeof("locking"));
#endif
		break;
	case BoltLockManager::State::kLockingCompleted:
		LOG_INF("Lock action completed");
		Nrf::GetBoard().GetLED(Nrf::DeviceLeds::LED2).Set(true);
#ifdef CONFIG_CHIP_NUS
		Nrf::GetNUSService().SendData("locked", sizeof("locked"));
#endif
		break;
	case BoltLockManager::State::kUnlockingInitiated:
		LOG_INF("Unlock action initiated");
		Nrf::GetBoard().GetLED(Nrf::DeviceLeds::LED2).Blink(50, 50);
#ifdef CONFIG_CHIP_NUS
		Nrf::GetNUSService().SendData("unlocking", sizeof("unlocking"));
#endif
		break;
	case BoltLockManager::State::kUnlockingCompleted:
		LOG_INF("Unlock action completed");
#ifdef CONFIG_CHIP_NUS
		Nrf::GetNUSService().SendData("unlocked", sizeof("unlocked"));
#endif
		Nrf::GetBoard().GetLED(Nrf::DeviceLeds::LED2).Set(false);
		break;
	}

	/* Handle changing attribute state in the application */
	Instance().UpdateClusterState(stateData);
}

void AppTask::UpdateClusterState(const BoltLockManager::StateData &stateData)
{
	BoltLockManager::StateData *stateDataCopy = Platform::New<BoltLockManager::StateData>(stateData);

	if (stateDataCopy == nullptr) {
		LOG_ERR("Failed to allocate memory for BoltLockManager::StateData");
		return;
	}

	CHIP_ERROR err = SystemLayer().ScheduleLambda([stateDataCopy]() {
		UpdateClusterStateHandler(*stateDataCopy);
		Platform::Delete(stateDataCopy);
	});

	if (err != CHIP_NO_ERROR) {
		LOG_ERR("Failed to schedule lambda: %" CHIP_ERROR_FORMAT, err.Format());
		Platform::Delete(stateDataCopy);
	}
}

void AppTask::UpdateClusterStateHandler(const BoltLockManager::StateData &stateData)
{
	using namespace chip::app::Clusters::DoorLock::Attributes;

	DlLockState newLockState;

	switch (stateData.mState) {
	case BoltLockManager::State::kLockingCompleted:
		newLockState = DlLockState::kLocked;
		break;
	case BoltLockManager::State::kUnlockingCompleted:
		newLockState = DlLockState::kUnlocked;
		break;
	default:
		newLockState = DlLockState::kNotFullyLocked;
		break;
	}

	Nullable<DlLockState> currentLockState;
	LockState::Get(kLockEndpointId, currentLockState);

	if (currentLockState.IsNull()) {
		/* Initialize lock state with start value, but not invoke lock/unlock. */
		LockState::Set(kLockEndpointId, newLockState);
	} else {
		LOG_INF("Updating LockState attribute");

		Nullable<uint16_t> userId;
		Nullable<List<const LockOpCredentials>> credentials;
#ifdef CONFIG_LOCK_PASS_CREDENTIALS_TO_SET_LOCK_STATE
		List<const LockOpCredentials> credentialList;
#endif

		if (!stateData.mValidatePINResult.IsNull()) {
			userId = { stateData.mValidatePINResult.Value().mUserId };

#ifdef CONFIG_LOCK_PASS_CREDENTIALS_TO_SET_LOCK_STATE
			/* `DoorLockServer::SetLockState` exptects list of `LockOpCredentials`,
			   however in case of PIN validation it makes no sense to have more than one
			   credential corresponding to validation result. For simplicity we wrap single
			   credential in list here. */
			credentialList = { &stateData.mValidatePINResult.Value().mCredential, 1 };
			credentials = { credentialList };
#endif
		}

		if (!DoorLockServer::Instance().SetLockState(kLockEndpointId, newLockState, stateData.mSource, userId,
							     credentials, stateData.mFabricIdx, stateData.mNodeId)) {
			LOG_ERR("Failed to update LockState attribute");
		}
	}
}

#ifdef CONFIG_CHIP_NUS
void AppTask::NUSLockCallback(void *context)
{
	LOG_DBG("Received LOCK command from NUS");
	if (BoltLockMgr().GetState().mState == BoltLockManager::State::kLockingCompleted ||
	    BoltLockMgr().GetState().mState == BoltLockManager::State::kLockingInitiated) {
		LOG_INF("Device is already locked");
	} else {
		Nrf::PostTask([] { LockActionEventHandler(); });
	}
}

void AppTask::NUSUnlockCallback(void *context)
{
	LOG_DBG("Received UNLOCK command from NUS");
	if (BoltLockMgr().GetState().mState == BoltLockManager::State::kUnlockingCompleted ||
	    BoltLockMgr().GetState().mState == BoltLockManager::State::kUnlockingInitiated) {
		LOG_INF("Device is already unlocked");
	} else {
		Nrf::PostTask([] { LockActionEventHandler(); });
	}
}
#endif

#ifdef CONFIG_NCS_MATTER_TEST_EVENT_TRIGGERS
CHIP_ERROR AppTask::DoorLockJammedEventCallback(Nrf::Matter::TestEventTrigger::TriggerValue)
{
	VerifyOrReturnError(DoorLockServer::Instance().SendLockAlarmEvent(kLockEndpointId, AlarmCodeEnum::kLockJammed),
			    CHIP_ERROR_INTERNAL);
	LOG_ERR("Event Trigger: Doorlock jammed.");
	return CHIP_NO_ERROR;
}
#endif

CHIP_ERROR AppTask::Init()
{
	/* Initialize Matter stack */
#ifdef CONFIG_THREAD_WIFI_SWITCHING
	/* In the Thread/Wi-Fi switchable mode, it is the ThreadWifiSwitch module that owns the NetworkCommissioning
	   instances, so offload the initialization module from controlling that by explicitly setting the
	   mNetworkingInstance parameter to nullptr. Otherwise, the initialization module instantiates the
	   NetworkCommissioning object and handles it by default internally. */
	ReturnErrorOnFailure(Nrf::Matter::PrepareServer(Nrf::Matter::InitData{ .mNetworkingInstance = nullptr }));
#else
	ReturnErrorOnFailure(Nrf::Matter::PrepareServer());
#endif

	if (!Nrf::GetBoard().Init(ButtonEventHandler)) {
		LOG_ERR("User interface initialization failed.");
		return CHIP_ERROR_INCORRECT_STATE;
	}

	/* Register Matter event handler that controls the connectivity status LED based on the captured Matter network
	 * state. */
	ReturnErrorOnFailure(Nrf::Matter::RegisterEventHandler(Nrf::Board::DefaultMatterEventHandler, 0));

#ifndef CONFIG_CHIP_FACTORY_RESET_ERASE_SETTINGS
	/* Register factory reset event handler.
	 * With this configuration we have to manually clean up the storage,
	 * as whole settings partition won't be erased.
	 * */
	ReturnErrorOnFailure(Nrf::Matter::RegisterEventHandler(AppFactoryResetHandler, 0));
#endif

#ifdef CONFIG_THREAD_WIFI_SWITCHING
	CHIP_ERROR err = ThreadWifiSwitch::StartCurrentTransport();
	if (err != CHIP_NO_ERROR) {
		LOG_ERR("ThreadWifiSwitch::StartCurrentTransport() failed: %" CHIP_ERROR_FORMAT, err.Format());
		return err;
	}

	k_timer_init(&sSwitchTransportTimer, &AppTask::SwitchTransportTimerTimeoutCallback, nullptr);
#endif

#ifdef CONFIG_CHIP_NUS
	/* Initialize Nordic UART Service for Lock purposes */
	if (!Nrf::GetNUSService().Init(kLockNUSPriority, kAdvertisingIntervalMin, kAdvertisingIntervalMax)) {
		ChipLogError(Zcl, "Cannot initialize NUS service");
	}
	Nrf::GetNUSService().RegisterCommand("Lock", sizeof("Lock"), NUSLockCallback, nullptr);
	Nrf::GetNUSService().RegisterCommand("Unlock", sizeof("Unlock"), NUSUnlockCallback, nullptr);
	if (!Nrf::GetNUSService().StartServer()) {
		LOG_ERR("GetNUSService().StartServer() failed");
	}
#endif

	/* Initialize lock manager */
	BoltLockMgr().Init(LockStateChanged);

	/* Register Door Lock test event trigger */
#ifdef CONFIG_NCS_MATTER_TEST_EVENT_TRIGGERS
	ReturnErrorOnFailure(Nrf::Matter::TestEventTrigger::Instance().RegisterTestEventTrigger(
		kDoorLockJammedEventTriggerId,
		Nrf::Matter::TestEventTrigger::EventTrigger{ 0, DoorLockJammedEventCallback }));
#endif

	return Nrf::Matter::StartServer();
}

CHIP_ERROR AppTask::StartApp()
{
	ReturnErrorOnFailure(Init());

	while (true) {
		Nrf::DispatchNextTask();
	}

	return CHIP_NO_ERROR;
}
```

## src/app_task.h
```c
/*
 * Copyright (c) 2021 Nordic Semiconductor ASA
 *
 * SPDX-License-Identifier: LicenseRef-Nordic-5-Clause
 */

#pragma once

#include "board/board.h"
#include "board/led_widget.h"
#include "bolt_lock_manager.h"

struct k_timer;
struct Identify;

#ifdef CONFIG_THREAD_WIFI_SWITCHING
enum class SwitchButtonAction : uint8_t { Pressed, Released };
#endif

#ifdef CONFIG_NCS_MATTER_TEST_EVENT_TRIGGERS
#include "event_triggers/event_triggers.h"
#endif

class AppTask {
public:
	static AppTask &Instance()
	{
		static AppTask sAppTask;
		return sAppTask;
	};

	CHIP_ERROR StartApp();

	void UpdateClusterState(const BoltLockManager::StateData &stateData);
	static void IdentifyStartHandler(Identify *);
	static void IdentifyStopHandler(Identify *);

private:
	CHIP_ERROR Init();

	static void LockActionEventHandler();
	static void ButtonEventHandler(Nrf::ButtonState state, Nrf::ButtonMask hasChanged);
	static void LockStateChanged(const BoltLockManager::StateData &stateData);
	static void UpdateClusterStateHandler(const BoltLockManager::StateData &stateData);

#ifdef CONFIG_THREAD_WIFI_SWITCHING
	static void SwitchTransportEventHandler();
	static void SwitchTransportTimerTimeoutCallback(k_timer *timer);
	static void SwitchTransportTriggerHandler(const SwitchButtonAction &action);
#endif

#ifdef CONFIG_CHIP_NUS
	static void NUSLockCallback(void *context);
	static void NUSUnlockCallback(void *context);
#endif

#ifdef CONFIG_NCS_MATTER_TEST_EVENT_TRIGGERS
	constexpr static Nrf::Matter::TestEventTrigger::EventTriggerId kDoorLockJammedEventTriggerId =
		0xFFFF'FFFF'3277'4000;
	static CHIP_ERROR DoorLockJammedEventCallback(Nrf::Matter::TestEventTrigger::TriggerValue);
#endif
};
```

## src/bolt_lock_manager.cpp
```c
/*
 * Copyright (c) 2021 Nordic Semiconductor ASA
 *
 * SPDX-License-Identifier: LicenseRef-Nordic-5-Clause
 */

#include "bolt_lock_manager.h"
#include "app/task_executor.h"

#include "app_task.h"

using namespace chip;

BoltLockManager BoltLockManager::sLock;

void BoltLockManager::Init(StateChangeCallback callback)
{
	mStateChangeCallback = callback;

	k_timer_init(&mActuatorTimer, &BoltLockManager::ActuatorTimerEventHandler, nullptr);
	k_timer_user_data_set(&mActuatorTimer, this);

	PinManager::Instance().Init();

	/* Set the default state */
	Nrf::GetBoard().GetLED(Nrf::DeviceLeds::LED2).Set(IsLocked());
}

bool BoltLockManager::GetUser(uint16_t userIndex, EmberAfPluginDoorLockUserInfo &user)
{
	return PinManager::Instance().GetUserInfo(userIndex, user);
}

bool BoltLockManager::SetUser(uint16_t userIndex, FabricIndex creator, FabricIndex modifier, const CharSpan &userName,
			      uint32_t uniqueId, UserStatusEnum userStatus, UserTypeEnum userType,
			      CredentialRuleEnum credentialRule, const CredentialStruct *credentials,
			      size_t totalCredentials)
{
	return PinManager::Instance().SetUser(userIndex, creator, modifier, userName, uniqueId, userStatus, userType,
					      credentialRule, credentials, totalCredentials);
}

bool BoltLockManager::GetCredential(uint16_t credentialIndex, CredentialTypeEnum credentialType,
				    EmberAfPluginDoorLockCredentialInfo &credential)
{
	return PinManager::Instance().GetCredential(credentialIndex, credentialType, credential);
}

bool BoltLockManager::SetCredential(uint16_t credentialIndex, FabricIndex creator, FabricIndex modifier,
				    DlCredentialStatus credentialStatus, CredentialTypeEnum credentialType,
				    const ByteSpan &secret)
{
	return PinManager::Instance().SetCredential(credentialIndex, creator, modifier, credentialStatus,
						    credentialType, secret);
}

#ifdef CONFIG_LOCK_SCHEDULES

DlStatus BoltLockManager::GetWeekDaySchedule(uint8_t weekdayIndex, uint16_t userIndex,
					     EmberAfPluginDoorLockWeekDaySchedule &schedule)
{
	return PinManager::Instance().GetWeekDaySchedule(weekdayIndex, userIndex, schedule);
}

DlStatus BoltLockManager::SetWeekDaySchedule(uint8_t weekdayIndex, uint16_t userIndex, DlScheduleStatus status,
					     DaysMaskMap daysMask, uint8_t startHour, uint8_t startMinute,
					     uint8_t endHour, uint8_t endMinute)
{
	return PinManager::Instance().SetWeekDaySchedule(weekdayIndex, userIndex, status, daysMask, startHour,
							 startMinute, endHour, endMinute);
}

DlStatus BoltLockManager::GetYearDaySchedule(uint8_t yearDayIndex, uint16_t userIndex,
					     EmberAfPluginDoorLockYearDaySchedule &schedule)
{
	return PinManager::Instance().GetYearDaySchedule(yearDayIndex, userIndex, schedule);
}

DlStatus BoltLockManager::SetYearDaySchedule(uint8_t yeardayIndex, uint16_t userIndex, DlScheduleStatus status,
					     uint32_t localStartTime, uint32_t localEndTime)
{
	return PinManager::Instance().SetYearDaySchedule(yeardayIndex, userIndex, status, localStartTime, localEndTime);
}

DlStatus BoltLockManager::GetHolidaySchedule(uint8_t holidayIndex, EmberAfPluginDoorLockHolidaySchedule &schedule)
{
	return PinManager::Instance().GetHolidaySchedule(holidayIndex, schedule);
}

DlStatus BoltLockManager::SetHolidaySchedule(uint8_t holidayIndex, DlScheduleStatus status, uint32_t localStartTime,
					     uint32_t localEndTime, OperatingModeEnum operatingMode)
{
	return PinManager::Instance().SetHolidaySchedule(holidayIndex, status, localStartTime, localEndTime,
							 operatingMode);
}

#endif /* CONFIG_LOCK_SCHEDULES */


bool BoltLockManager::ValidatePIN(const Optional<ByteSpan> &pinCode, OperationErrorEnum &err)
{
	return PinManager::Instance().ValidatePIN(pinCode, err);
}

void BoltLockManager::SetRequirePIN(bool require)
{
	return PinManager::Instance().SetRequirePIN(require);
}
bool BoltLockManager::GetRequirePIN()
{
	return PinManager::Instance().GetRequirePIN();
}

void BoltLockManager::Lock(OperationSource source)
{
	VerifyOrReturn(mState != State::kLockingCompleted);
	SetState(State::kLockingInitiated, source);

	mActuatorOperationSource = source;
	k_timer_start(&mActuatorTimer, K_MSEC(kActuatorMovementTimeMs), K_NO_WAIT);
}

void BoltLockManager::Unlock(OperationSource source)
{
	VerifyOrReturn(mState != State::kUnlockingCompleted);
	SetState(State::kUnlockingInitiated, source);

	mActuatorOperationSource = source;
	k_timer_start(&mActuatorTimer, K_MSEC(kActuatorMovementTimeMs), K_NO_WAIT);
}

void BoltLockManager::ActuatorTimerEventHandler(k_timer *timer)
{
	/*
	 * The timer event handler is called in the context of the system clock ISR.
	 * Post an event to the application task queue to process the event in the
	 * context of the application thread.
	 */

	BoltLockManagerEvent event;
	event.manager = static_cast<BoltLockManager *>(k_timer_user_data_get(timer));
	Nrf::PostTask([event] { ActuatorAppEventHandler(event); });
}

void BoltLockManager::ActuatorAppEventHandler(const BoltLockManagerEvent &event)
{
	BoltLockManager *lock = reinterpret_cast<BoltLockManager *>(event.manager);

	switch (lock->mState) {
	case State::kLockingInitiated:
		lock->SetState(State::kLockingCompleted, lock->mActuatorOperationSource);
		break;
	case State::kUnlockingInitiated:
		lock->SetState(State::kUnlockingCompleted, lock->mActuatorOperationSource);
		break;
	default:
		break;
	}
}

void BoltLockManager::SetState(State state, OperationSource source)
{
	mState = state;

	if (mStateChangeCallback != nullptr) {
		mStateChangeCallback(state, source);
	}
}
```

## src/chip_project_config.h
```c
/*
 * Copyright (c) 2021 Nordic Semiconductor ASA
 *
 * SPDX-License-Identifier: LicenseRef-Nordic-5-Clause
 */

/**
 *    @file
 *          Example project configuration file for CHIP.
 *
 *          This is a place to put application or project-specific overrides
 *          to the default configuration values for general CHIP features.
 *
 */

#pragma once

/* Use a default pairing code if one hasn't been provisioned in flash. */
#define CHIP_DEVICE_CONFIG_USE_TEST_SETUP_PIN_CODE 20202021
#define CHIP_DEVICE_CONFIG_USE_TEST_SETUP_DISCRIMINATOR 0xF00

#ifdef CONFIG_NRF_WIFI_LOW_POWER
/* Enable overriding MRP params. 
This config allows to increase MRP active interval according to current DTIM interval and the beacon interval.
*/
#define CHIP_CONFIG_ALLOW_RUNTIME_MRP_OVERRIDE 1
#endif
```
